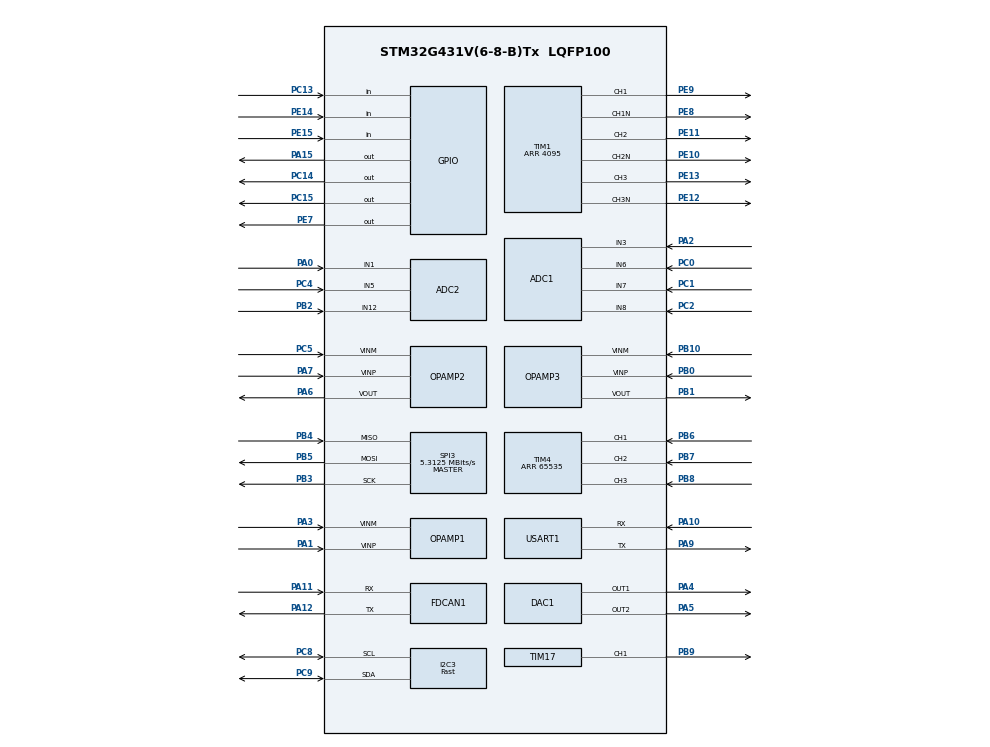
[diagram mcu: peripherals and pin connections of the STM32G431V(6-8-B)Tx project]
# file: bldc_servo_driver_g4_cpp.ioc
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ADC1.Channel-0\#ChannelRegularConversion=ADC_CHANNEL_3
ADC1.Channel-1\#ChannelRegularConversion=ADC_CHANNEL_12
ADC1.Channel-2\#ChannelRegularConversion=ADC_CHANNEL_6
ADC1.Channel-3\#ChannelRegularConversion=ADC_CHANNEL_7
ADC1.Channel-5\#ChannelRegularConversion=ADC_CHANNEL_8
ADC1.Channel-6\#ChannelRegularConversion=ADC_CHANNEL_TEMPSENSOR_ADC1
ADC1.ClockPrescaler=ADC_CLOCK_SYNC_PCLK_DIV4
ADC1.DMAContinuousRequests=ENABLE
ADC1.DiscontinuousConvMode=ENABLE
ADC1.EOCSelection=ADC_EOC_SEQ_CONV
ADC1.ExternalTrigConv=ADC_EXTERNALTRIG_T1_TRGO
ADC1.NbrOfConversion=6
ADC1.NbrOfConversionFlag=1
ADC1.NbrOfDiscConversion=1
ADC1.OffsetNumber-0\#ChannelRegularConversion=ADC_OFFSET_NONE
ADC1.OffsetNumber-1\#ChannelRegularConversion=ADC_OFFSET_NONE
ADC1.OffsetNumber-2\#ChannelRegularConversion=ADC_OFFSET_NONE
ADC1.OffsetNumber-3\#ChannelRegularConversion=ADC_OFFSET_NONE
ADC1.OffsetNumber-5\#ChannelRegularConversion=ADC_OFFSET_NONE
ADC1.OffsetNumber-6\#ChannelRegularConversion=ADC_OFFSET_NONE
ADC1.Overrun=ADC_OVR_DATA_OVERWRITTEN
ADC1.Rank-0\#ChannelRegularConversion=1
ADC1.Rank-1\#ChannelRegularConversion=2
ADC1.Rank-2\#ChannelRegularConversion=3
ADC1.Rank-3\#ChannelRegularConversion=4
ADC1.Rank-5\#ChannelRegularConversion=5
ADC1.Rank-6\#ChannelRegularConversion=6
ADC1.SamplingTime-0\#ChannelRegularConversion=ADC_SAMPLETIME_12CYCLES_5
ADC1.SamplingTime-1\#ChannelRegularConversion=ADC_SAMPLETIME_12CYCLES_5
ADC1.SamplingTime-2\#ChannelRegularConversion=ADC_SAMPLETIME_12CYCLES_5
ADC1.SamplingTime-3\#ChannelRegularConversion=ADC_SAMPLETIME_12CYCLES_5
ADC1.SamplingTime-5\#ChannelRegularConversion=ADC_SAMPLETIME_12CYCLES_5
ADC1.SamplingTime-6\#ChannelRegularConversion=ADC_SAMPLETIME_12CYCLES_5
ADC1.master=1
ADC2.Channel-0\#ChannelRegularConversion=ADC_CHANNEL_3
ADC2.Channel-1\#ChannelRegularConversion=ADC_CHANNEL_12
ADC2.Channel-2\#ChannelRegularConversion=ADC_CHANNEL_5
ADC2.Channel-3\#ChannelRegularConversion=ADC_CHANNEL_1
ADC2.DMAContinuousRequests=ENABLE
ADC2.DiscontinuousConvMode=ENABLE
ADC2.EOCSelection=ADC_EOC_SEQ_CONV
ADC2.ExternalTrigConv=ADC_EXTERNALTRIG_T1_TRGO
ADC2.NbrOfConversion=4
ADC2.NbrOfConversionFlag=1
ADC2.OffsetNumber-0\#ChannelRegularConversion=ADC_OFFSET_NONE
ADC2.OffsetNumber-1\#ChannelRegularConversion=ADC_OFFSET_NONE
ADC2.OffsetNumber-2\#ChannelRegularConversion=ADC_OFFSET_NONE
ADC2.OffsetNumber-3\#ChannelRegularConversion=ADC_OFFSET_NONE
ADC2.Overrun=ADC_OVR_DATA_OVERWRITTEN
ADC2.Rank-0\#ChannelRegularConversion=1
ADC2.Rank-1\#ChannelRegularConversion=2
ADC2.Rank-2\#ChannelRegularConversion=3
ADC2.Rank-3\#ChannelRegularConversion=4
ADC2.SamplingTime-0\#ChannelRegularConversion=ADC_SAMPLETIME_12CYCLES_5
ADC2.SamplingTime-1\#ChannelRegularConversion=ADC_SAMPLETIME_24CYCLES_5
ADC2.SamplingTime-2\#ChannelRegularConversion=ADC_SAMPLETIME_24CYCLES_5
ADC2.SamplingTime-3\#ChannelRegularConversion=ADC_SAMPLETIME_12CYCLES_5
ARM.CMSIS.5.6.0.CMSISJjDSP=Library
DAC1.DAC_Channel-DAC_OUT2=DAC_CHANNEL_2
Dma.ADC1.2.Direction=DMA_PERIPH_TO_MEMORY
Dma.ADC1.2.EventEnable=DISABLE
Dma.ADC1.2.Instance=DMA2_Channel1
Dma.ADC1.2.MemDataAlignment=DMA_MDATAALIGN_HALFWORD
Dma.ADC1.2.MemInc=DMA_MINC_ENABLE
Dma.ADC1.2.Mode=DMA_CIRCULAR
Dma.ADC1.2.PeriphDataAlignment=DMA_PDATAALIGN_HALFWORD
Dma.ADC1.2.PeriphInc=DMA_PINC_DISABLE
Dma.ADC1.2.Polarity=HAL_DMAMUX_REQ_GEN_RISING
Dma.ADC1.2.Priority=DMA_PRIORITY_HIGH
Dma.ADC1.2.RequestNumber=1
Dma.ADC1.2.SignalID=NONE
Dma.ADC1.2.SyncEnable=DISABLE
Dma.ADC1.2.SyncPolarity=HAL_DMAMUX_SYNC_NO_EVENT
Dma.ADC1.2.SyncRequestNumber=1
Dma.ADC1.2.SyncSignalID=NONE
Dma.ADC2.3.Direction=DMA_PERIPH_TO_MEMORY
Dma.ADC2.3.EventEnable=DISABLE
Dma.ADC2.3.Instance=DMA2_Channel2
Dma.ADC2.3.MemDataAlignment=DMA_MDATAALIGN_HALFWORD
Dma.ADC2.3.MemInc=DMA_MINC_ENABLE
Dma.ADC2.3.Mode=DMA_CIRCULAR
Dma.ADC2.3.PeriphDataAlignment=DMA_PDATAALIGN_HALFWORD
Dma.ADC2.3.PeriphInc=DMA_PINC_DISABLE
Dma.ADC2.3.Polarity=HAL_DMAMUX_REQ_GEN_RISING
Dma.ADC2.3.Priority=DMA_PRIORITY_HIGH
Dma.ADC2.3.RequestNumber=1
Dma.ADC2.3.SignalID=NONE
Dma.ADC2.3.SyncEnable=DISABLE
Dma.ADC2.3.SyncPolarity=HAL_DMAMUX_SYNC_NO_EVENT
Dma.ADC2.3.SyncRequestNumber=1
Dma.ADC2.3.SyncSignalID=NONE
Dma.I2C3_RX.0.Direction=DMA_PERIPH_TO_MEMORY
Dma.I2C3_RX.0.EventEnable=DISABLE
Dma.I2C3_RX.0.Instance=DMA1_Channel1
Dma.I2C3_RX.0.MemDataAlignment=DMA_MDATAALIGN_BYTE
Dma.I2C3_RX.0.MemInc=DMA_MINC_ENABLE
Dma.I2C3_RX.0.Mode=DMA_NORMAL
Dma.I2C3_RX.0.PeriphDataAlignment=DMA_PDATAALIGN_BYTE
Dma.I2C3_RX.0.PeriphInc=DMA_PINC_DISABLE
Dma.I2C3_RX.0.Polarity=HAL_DMAMUX_REQ_GEN_RISING
Dma.I2C3_RX.0.Priority=DMA_PRIORITY_MEDIUM
Dma.I2C3_RX.0.RequestNumber=1
Dma.I2C3_RX.0.SignalID=NONE
Dma.I2C3_RX.0.SyncEnable=DISABLE
Dma.I2C3_RX.0.SyncPolarity=HAL_DMAMUX_SYNC_NO_EVENT
Dma.I2C3_RX.0.SyncRequestNumber=1
Dma.I2C3_RX.0.SyncSignalID=NONE
Dma.I2C3_TX.1.Direction=DMA_MEMORY_TO_PERIPH
Dma.I2C3_TX.1.EventEnable=DISABLE
Dma.I2C3_TX.1.Instance=DMA1_Channel2
Dma.I2C3_TX.1.MemDataAlignment=DMA_MDATAALIGN_BYTE
Dma.I2C3_TX.1.MemInc=DMA_MINC_ENABLE
Dma.I2C3_TX.1.Mode=DMA_NORMAL
Dma.I2C3_TX.1.PeriphDataAlignment=DMA_PDATAALIGN_BYTE
Dma.I2C3_TX.1.PeriphInc=DMA_PINC_DISABLE
Dma.I2C3_TX.1.Polarity=HAL_DMAMUX_REQ_GEN_RISING
Dma.I2C3_TX.1.Priority=DMA_PRIORITY_MEDIUM
Dma.I2C3_TX.1.RequestNumber=1
Dma.I2C3_TX.1.SignalID=NONE
Dma.I2C3_TX.1.SyncEnable=DISABLE
Dma.I2C3_TX.1.SyncPolarity=HAL_DMAMUX_SYNC_NO_EVENT
Dma.I2C3_TX.1.SyncRequestNumber=1
Dma.I2C3_TX.1.SyncSignalID=NONE
Dma.Request0=I2C3_RX
Dma.Request1=I2C3_TX
Dma.Request2=ADC1
Dma.Request3=ADC2
Dma.Request4=USART1_RX
Dma.Request5=USART1_TX
Dma.USART1_RX.4.Direction=DMA_PERIPH_TO_MEMORY
Dma.USART1_RX.4.EventEnable=DISABLE
Dma.USART1_RX.4.Instance=DMA1_Channel3
Dma.USART1_RX.4.MemDataAlignment=DMA_MDATAALIGN_BYTE
Dma.USART1_RX.4.MemInc=DMA_MINC_ENABLE
Dma.USART1_RX.4.Mode=DMA_CIRCULAR
Dma.USART1_RX.4.PeriphDataAlignment=DMA_PDATAALIGN_BYTE
Dma.USART1_RX.4.PeriphInc=DMA_PINC_DISABLE
Dma.USART1_RX.4.Polarity=HAL_DMAMUX_REQ_GEN_RISING
Dma.USART1_RX.4.Priority=DMA_PRIORITY_HIGH
Dma.USART1_RX.4.RequestNumber=1
Dma.USART1_RX.4.SignalID=NONE
Dma.USART1_RX.4.SyncEnable=DISABLE
Dma.USART1_RX.4.SyncPolarity=HAL_DMAMUX_SYNC_NO_EVENT
Dma.USART1_RX.4.SyncRequestNumber=1
Dma.USART1_RX.4.SyncSignalID=NONE
Dma.USART1_TX.5.Direction=DMA_MEMORY_TO_PERIPH
Dma.USART1_TX.5.EventEnable=DISABLE
Dma.USART1_TX.5.Instance=DMA1_Channel4
Dma.USART1_TX.5.MemDataAlignment=DMA_MDATAALIGN_BYTE
Dma.USART1_TX.5.MemInc=DMA_MINC_ENABLE
Dma.USART1_TX.5.Mode=DMA_NORMAL
Dma.USART1_TX.5.PeriphDataAlignment=DMA_PDATAALIGN_BYTE
Dma.USART1_TX.5.PeriphInc=DMA_PINC_DISABLE
Dma.USART1_TX.5.Polarity=HAL_DMAMUX_REQ_GEN_RISING
Dma.USART1_TX.5.Priority=DMA_PRIORITY_HIGH
Dma.USART1_TX.5.RequestNumber=1
Dma.USART1_TX.5.SignalID=NONE
Dma.USART1_TX.5.SyncEnable=DISABLE
Dma.USART1_TX.5.SyncPolarity=HAL_DMAMUX_SYNC_NO_EVENT
Dma.USART1_TX.5.SyncRequestNumber=1
Dma.USART1_TX.5.SyncSignalID=NONE
I2C3.Analog_Filter=I2C_ANALOGFILTER_DISABLE
I2C3.I2C_Speed_Mode=I2C_Fast
I2C3.Timing=0x0010071B
Mcu.Family=STM32G4
Mcu.Name=STM32G431V(6-8-B)Tx
Mcu.Package=LQFP100
NVIC.DMA1_Channel1_IRQn=true\:6\:0\:true\:false\:true\:false\:true
NVIC.DMA1_Channel2_IRQn=true\:6\:0\:true\:false\:true\:false\:true
NVIC.PriorityGroup=NVIC_PRIORITYGROUP_4
NVIC.TIM4_IRQn=true\:2\:0\:true\:false\:true\:true\:true
NVIC.TIM6_DAC_IRQn=true\:8\:0\:true\:false\:true\:true\:true
NVIC.TIM7_IRQn=true\:3\:0\:true\:false\:true\:true\:true
NVIC.USART1_IRQn=true\:2\:0\:true\:false\:true\:true\:true
PA0.Mode=IN1-Single-Ended
PA0.Signal=ADC2_IN1
PA1.Mode=Standalone
PA1.Signal=OPAMP1_VINP
PA10.Mode=Asynchronous
PA10.Signal=USART1_RX
PA11.Mode=FDCAN_Activate
PA11.Signal=FDCAN1_RX
PA12.Mode=FDCAN_Activate
PA12.Signal=FDCAN1_TX
PA13.Mode=Serial_Wire
PA13.Signal=SYS_JTMS-SWDIO
PA14.Mode=Serial_Wire
PA14.Signal=SYS_JTCK-SWCLK
PA15.Signal=GPIO_Output
PA2.Signal=SharedAnalog_PA2
PA3.Mode=Standalone
PA3.Signal=OPAMP1_VINM
PA4.Signal=COMP_DAC11_group
PA5.Signal=COMP_DAC12_group
PA6.Signal=SharedAnalog_PA6
PA7.Mode=Standalone
PA7.Signal=OPAMP2_VINP
PA9.Mode=Asynchronous
PA9.Signal=USART1_TX
PB0.Mode=Standalone
PB0.Signal=OPAMP3_VINP
PB1.Signal=SharedAnalog_PB1
PB10.Mode=Standalone
PB10.Signal=OPAMP3_VINM
PB2.Mode=IN12-Single-Ended
PB2.Signal=ADC2_IN12
PB3.Mode=Full_Duplex_Master
PB3.Signal=SPI3_SCK
PB4.Mode=Full_Duplex_Master
PB4.Signal=SPI3_MISO
PB5.Mode=Full_Duplex_Master
PB5.Signal=SPI3_MOSI
PB6.Signal=S_TIM4_CH1
PB7.Signal=S_TIM4_CH2
PB8-BOOT0.Signal=S_TIM4_CH3
PB9.Signal=S_TIM17_CH1
PC0.Mode=IN6-Single-Ended
PC0.Signal=ADC1_IN6
PC1.Mode=IN7-Single-Ended
PC1.Signal=ADC1_IN7
PC13.Signal=GPIO_Input
PC14-OSC32_IN.Signal=GPIO_Output
PC15-OSC32_OUT.Signal=GPIO_Output
PC2.Mode=IN8-Single-Ended
PC2.Signal=ADC1_IN8
PC4.Mode=IN5-Single-Ended
PC4.Signal=ADC2_IN5
PC5.Mode=Standalone
PC5.Signal=OPAMP2_VINM
PC8.GPIO_Pu=GPIO_PULLUP
PC8.Mode=I2C
PC8.Signal=I2C3_SCL
PC9.GPIO_Pu=GPIO_PULLUP
PC9.Mode=I2C
PC9.Signal=I2C3_SDA
PE10.Mode=PWM Generation2 CH2 CH2N
PE10.Signal=TIM1_CH2N
PE11.Signal=S_TIM1_CH2
PE12.Mode=PWM Generation3 CH3 CH3N
PE12.Signal=TIM1_CH3N
PE13.Signal=S_TIM1_CH3
PE14.GPIO_PuPd=GPIO_PULLUP
PE14.Signal=GPIO_Input
PE15.GPIO_PuPd=GPIO_PULLUP
PE15.Signal=GPIO_Input
PE7.PinState=GPIO_PIN_SET
PE7.Signal=GPIO_Output
PE8.Mode=PWM Generation1 CH1 CH1N
PE8.Signal=TIM1_CH1N
PE9.Signal=S_TIM1_CH1
PF0-OSC_IN.Mode=HSE-External-Oscillator
PF0-OSC_IN.Signal=RCC_OSC_IN
PF1-OSC_OUT.Mode=HSE-External-Oscillator
PF1-OSC_OUT.Signal=RCC_OSC_OUT
ProjectManager.HeapSize=0x200
ProjectManager.StackSize=0x400
ProjectManager.TargetToolchain=Makefile
RCC.ADC12CLockSelection=RCC_ADC12CLKSOURCE_PLL
RCC.ADC12Freq_Value=42500000
RCC.AHBFreq_Value=170000000
RCC.APB1Freq_Value=170000000
RCC.APB1TimFreq_Value=170000000
RCC.APB2Freq_Value=170000000
RCC.APB2TimFreq_Value=170000000
RCC.CortexFreq_Value=170000000
RCC.EXTERNAL_CLOCK_VALUE=12288000
RCC.HCLKFreq_Value=170000000
RCC.HSE_VALUE=25000000
RCC.HSI48_VALUE=48000000
RCC.HSI_VALUE=16000000
RCC.I2C3CLockSelection=RCC_I2C3CLKSOURCE_HSI
RCC.LSE_VALUE=32768
RCC.PLLM=RCC_PLLM_DIV5
RCC.PLLN=68
RCC.PLLP=RCC_PLLP_DIV8
RCC.PLLSourceVirtual=RCC_PLLSOURCE_HSE
RCC.SYSCLKFreq_VALUE=170000000
RCC.SYSCLKSource=RCC_SYSCLKSOURCE_PLLCLK
RCC.USART1CLockSelection=RCC_USART1CLKSOURCE_HSI
RCC.USBFreq_Value=170000000
RCC.VCOOutputFreq_Value=340000000
SH.COMP_DAC11_group.0=DAC1_OUT1,DAC_OUT1
SH.COMP_DAC12_group.0=DAC1_OUT2,DAC_OUT2
SH.S_TIM17_CH1.0=TIM17_CH1,PWM Generation1 CH1
SH.S_TIM1_CH1.0=TIM1_CH1,PWM Generation1 CH1 CH1N
SH.S_TIM1_CH2.0=TIM1_CH2,PWM Generation2 CH2 CH2N
SH.S_TIM1_CH3.0=TIM1_CH3,PWM Generation3 CH3 CH3N
SH.S_TIM4_CH1.0=TIM4_CH1,Xored_Inputs_Hall_Sensor_Interface
SH.S_TIM4_CH2.0=TIM4_CH2,Xored_Inputs_Hall_Sensor_Interface
SH.S_TIM4_CH3.0=TIM4_CH3,Xored_Inputs_Hall_Sensor_Interface
SH.SharedAnalog_PA2.0=ADC1_IN3,IN3-Single-Ended
SH.SharedAnalog_PA2.1=OPAMP1_VOUT,Standalone
SH.SharedAnalog_PA6.0=OPAMP2_VOUT,Standalone
SH.SharedAnalog_PA6.1=ADC2_IN3,IN3-Single-Ended
SH.SharedAnalog_PB1.0=OPAMP3_VOUT,Standalone
SH.SharedAnalog_PB1.1=ADC1_IN12,IN12-Single-Ended
SPI3.BaudRatePrescaler=SPI_BAUDRATEPRESCALER_32
SPI3.CalculateBaudRate=5.3125 MBits/s
SPI3.Direction=SPI_DIRECTION_2LINES
SPI3.Mode=SPI_MODE_MASTER
SPI3.VirtualType=VM_MASTER
TIM1.Channel-PWM\ Generation1\ CH1\ CH1N=TIM_CHANNEL_1
TIM1.Channel-PWM\ Generation2\ CH2\ CH2N=TIM_CHANNEL_2
TIM1.Channel-PWM\ Generation3\ CH3\ CH3N=TIM_CHANNEL_3
TIM1.CounterMode=TIM_COUNTERMODE_CENTERALIGNED1
TIM1.OCIdleState_1=TIM_OCIDLESTATE_SET
TIM1.OCIdleState_2=TIM_OCIDLESTATE_SET
TIM1.OCIdleState_3=TIM_OCIDLESTATE_SET
TIM1.OCNIdleState_1=TIM_OCNIDLESTATE_SET
TIM1.OCNIdleState_2=TIM_OCNIDLESTATE_SET
TIM1.OCNIdleState_3=TIM_OCNIDLESTATE_SET
TIM1.PeriodNoDither=4095
TIM1.TIM_MasterOutputTrigger=TIM_TRGO_UPDATE
TIM17.Channel=TIM_CHANNEL_1
TIM17.PeriodNoDither=10000
TIM17.Prescaler=17000
TIM2.Prescaler=169
TIM4.PeriodNoDither=65535
TIM6.PeriodNoDither=9999
TIM6.Prescaler=169
TIM7.PeriodNoDither=99
TIM7.Prescaler=169
USART1.VirtualMode-Asynchronous=VM_ASYNC
VP_ADC1_TempSens_Input.Mode=IN-TempSens
VP_ARM.CMSIS_VS_CMSISJjDSP_1.7.0_5.6.0.Mode=CMSISJjDSP
VP_CORDIC_VS_CORDIC.Mode=CORDIC_Activate
VP_SYS_VS_DBSignals.Mode=DisableDeadBatterySignals
VP_TIM17_VS_ClockSourceINT.Mode=Enable_Timer
VP_TIM1_VS_ClockSourceINT.Mode=Internal
VP_TIM2_VS_ClockSourceINT.Mode=Internal
VP_TIM6_VS_ClockSourceINT.Mode=Enable_Timer
VP_TIM7_VS_ClockSourceINT.Mode=Enable_Timer
board=custom

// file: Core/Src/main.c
/* USER CODE BEGIN Header */
/**
  ******************************************************************************
  * @file           : main.c
  * @brief          : Main program body
  ******************************************************************************
  * @attention
  *
  * <h2><center>&copy; Copyright (c) 2021 STMicroelectronics.
  * All rights reserved.</center></h2>
  *
  * This software component is licensed by ST under BSD 3-Clause license,
  * the "License"; You may not use this file except in compliance with the
  * License. You may obtain a copy of the License at:
  *                        opensource.org/licenses/BSD-3-Clause
  *
  ******************************************************************************
  */
/* USER CODE END Header */
#include "main.h"
#include "adc.h"
#include "cordic.h"
#include "dac.h"
#include "dma.h"
#include "fdcan.h"
#include "i2c.h"
#include "opamp.h"
#include "spi.h"
#include "tim.h"
#include "usart.h"
#include "gpio.h"

/* USER CODE BEGIN Includes */
#include "wrapper_main.hpp"
/* USER CODE END Includes */

void SystemClock_Config(void);

int main(void)
{

  /* MCU Configuration--------------------------------------------------------*/

  /* Reset of all peripherals, Initializes the Flash interface and the Systick. */
  HAL_Init();

  /* Configure the system clock */
  SystemClock_Config();

  /* Initialize all configured peripherals */
  MX_GPIO_Init();
  MX_DMA_Init();
  MX_ADC1_Init();
  MX_ADC2_Init();
  MX_DAC1_Init();
  MX_I2C3_Init();
  MX_OPAMP1_Init();
  MX_OPAMP2_Init();
  MX_OPAMP3_Init();
  MX_SPI3_Init();
  MX_TIM1_Init();
  MX_TIM4_Init();
  MX_TIM17_Init();
  MX_DMA_Init();
  MX_USART1_UART_Init();
  MX_CORDIC_Init();
  MX_TIM2_Init();
  MX_TIM6_Init();
  MX_TIM7_Init();
  MX_FDCAN1_Init();
  /* USER CODE BEGIN 2 */
  cpp_wrapper_main_setup();
  /* USER CODE END 2 */

  /* Infinite loop */
  /* USER CODE BEGIN WHILE */
  while (1)
  {
    cpp_wrapper_main_loop();
    /* USER CODE END WHILE */

  }
}

void SystemClock_Config(void)
{
  LL_FLASH_SetLatency(LL_FLASH_LATENCY_4);
  while(LL_FLASH_GetLatency() != LL_FLASH_LATENCY_4)
  {
  }
  LL_PWR_EnableRange1BoostMode();
  LL_RCC_HSE_Enable();
   /* Wait till HSE is ready */
  while(LL_RCC_HSE_IsReady() != 1)
  {
  }

  LL_RCC_HSI_Enable();
   /* Wait till HSI is ready */
  while(LL_RCC_HSI_IsReady() != 1)
  {
  }

  LL_RCC_HSI_SetCalibTrimming(64);
  LL_RCC_PLL_ConfigDomain_SYS(LL_RCC_PLLSOURCE_HSE, LL_RCC_PLLM_DIV_5, 68, LL_RCC_PLLR_DIV_2);
  LL_RCC_PLL_ConfigDomain_ADC(LL_RCC_PLLSOURCE_HSE, LL_RCC_PLLM_DIV_5, 68, LL_RCC_PLLP_DIV_8);
  LL_RCC_PLL_EnableDomain_SYS();
  LL_RCC_PLL_EnableDomain_ADC();
  LL_RCC_PLL_Enable();
   /* Wait till PLL is ready */
  while(LL_RCC_PLL_IsReady() != 1)
  {
  }

  LL_RCC_SetSysClkSource(LL_RCC_SYS_CLKSOURCE_PLL);
  LL_RCC_SetAHBPrescaler(LL_RCC_SYSCLK_DIV_2);
   /* Wait till System clock is ready */
  while(LL_RCC_GetSysClkSource() != LL_RCC_SYS_CLKSOURCE_STATUS_PLL)
  {
  }

  /* Insure 1��s transition state at intermediate medium speed clock based on DWT */
  CoreDebug->DEMCR |= CoreDebug_DEMCR_TRCENA_Msk;
  DWT->CTRL |= DWT_CTRL_CYCCNTENA_Msk;
  DWT->CYCCNT = 0;
  while(DWT->CYCCNT < 100);
  /* Set AHB prescaler*/
  LL_RCC_SetAHBPrescaler(LL_RCC_SYSCLK_DIV_1);
  LL_RCC_SetAPB1Prescaler(LL_RCC_APB1_DIV_1);
  LL_RCC_SetAPB2Prescaler(LL_RCC_APB2_DIV_1);
  LL_SetSystemCoreClock(170000000);

   /* Update the time base */
  if (HAL_InitTick (TICK_INT_PRIORITY) != HAL_OK)
  {
    Error_Handler();
  }
  LL_RCC_SetFDCANClockSource(LL_RCC_FDCAN_CLKSOURCE_PCLK1);
  LL_RCC_SetUSARTClockSource(LL_RCC_USART1_CLKSOURCE_HSI);
  LL_RCC_SetI2CClockSource(LL_RCC_I2C3_CLKSOURCE_HSI);
  LL_RCC_SetADCClockSource(LL_RCC_ADC12_CLKSOURCE_PLL);
}

void Error_Handler(void)
{
}

/************************ (C) COPYRIGHT STMicroelectronics *****END OF FILE****/
